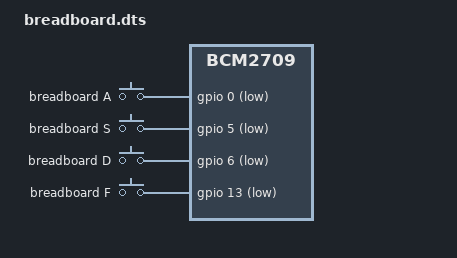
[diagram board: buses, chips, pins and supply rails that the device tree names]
/dts-v1/;
    /plugin/;
    / {
       compatible = "brcm,bcm2835", "brcm,bcm2708", "brcm,bcm2709";
       
       fragment@0 {
          target-path = "/";
          __overlay__ {
             keypad: breadboard_keys {
                compatible = "gpio-keys";
                #address-cells = <1>;
                #size-cells = <0>;
                button@0 {
                   label = "breadboard A";
                   linux,code = <30>;
                   gpios = <&gpio 0 1>;
                };
                button@5 {
                   label = "breadboard S";
                   linux,code = <31>;
                   gpios = <&gpio 5 1>;
                };
                button@6 {
                   label = "breadboard D";
                   linux,code = <32>;
                   gpios = <&gpio 6 1>;
                };
                button@13 {
                   label = "breadboard F";
                   linux,code = <33>;
                   gpios = <&gpio 13 1>;
                };
             };
          };
       };
    };
